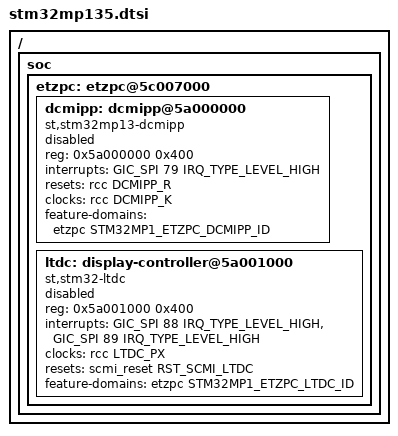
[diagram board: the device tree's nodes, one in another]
// SPDX-License-Identifier: (GPL-2.0+ OR BSD-3-Clause)
/*
 * Copyright (C) STMicroelectronics 2021 - All Rights Reserved
 * Author: Alexandre Torgue <alexandre.torgue@foss.st.com> for STMicroelectronics.
 */

#include "stm32mp133.dtsi"

/ {
	soc {
		etzpc: etzpc@5c007000 {
			dcmipp: dcmipp@5a000000 {
				compatible = "st,stm32mp13-dcmipp";
				reg = <0x5a000000 0x400>;
				interrupts = <GIC_SPI 79 IRQ_TYPE_LEVEL_HIGH>;
				resets = <&rcc DCMIPP_R>;
				clocks = <&rcc DCMIPP_K>;
				clock-names = "kclk";
				feature-domains = <&etzpc STM32MP1_ETZPC_DCMIPP_ID>;
				status = "disabled";
			};

			ltdc: display-controller@5a001000 {
				compatible = "st,stm32-ltdc";
				reg = <0x5a001000 0x400>;
				interrupts = <GIC_SPI 88 IRQ_TYPE_LEVEL_HIGH>,
					     <GIC_SPI 89 IRQ_TYPE_LEVEL_HIGH>;
				clocks = <&rcc LTDC_PX>;
				clock-names = "lcd";
				resets = <&scmi_reset RST_SCMI_LTDC>;
				feature-domains = <&etzpc STM32MP1_ETZPC_LTDC_ID>;
				status = "disabled";
			};
		};
	};
};
